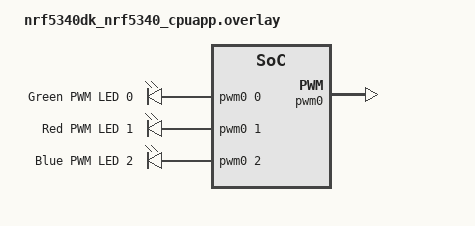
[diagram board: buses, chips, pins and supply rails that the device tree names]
/ {
    pwmleds {
        compatible = "pwm-leds";
        pwm_led0_green: pwm_led_0 {
            pwms = <&pwm0 0 PWM_MSEC(10) PWM_POLARITY_INVERTED>;
            label = "Green PWM LED 0";
        };
        pwm_led1_red: pwm_led_1 {
            pwms = <&pwm0 1 PWM_MSEC(10) PWM_POLARITY_INVERTED>;
            label = "Red PWM LED 1";
        };
        pwm_led2_blue: pwm_led_2 {
            pwms = <&pwm0 2 PWM_MSEC(10) PWM_POLARITY_INVERTED>;
            label = "Blue PWM LED 2";
        };
    };
    aliases {
        pwm-led0 = &pwm_led0_green;
        pwm-led1 = &pwm_led1_red;
        pwm-led2 = &pwm_led2_blue;
        green-pwm-led = &pwm_led0_green;
        red-pwm-led = &pwm_led1_red;
        blue-pwm-led = &pwm_led2_blue;
    };
};
&pwm0 {
	status = "okay";
	pinctrl-0 = <&pwm0_default>;
	pinctrl-1 = <&pwm0_sleep>;
	pinctrl-names = "default", "sleep";
};
&pinctrl {
    pwm0_default {
        group1 {
            psels = <NRF_PSEL(PWM_OUT0, 1, 10)>,
                    <NRF_PSEL(PWM_OUT1, 1, 9)>,
                    <NRF_PSEL(PWM_OUT2, 1, 11)>;
        };
    };
    
};
